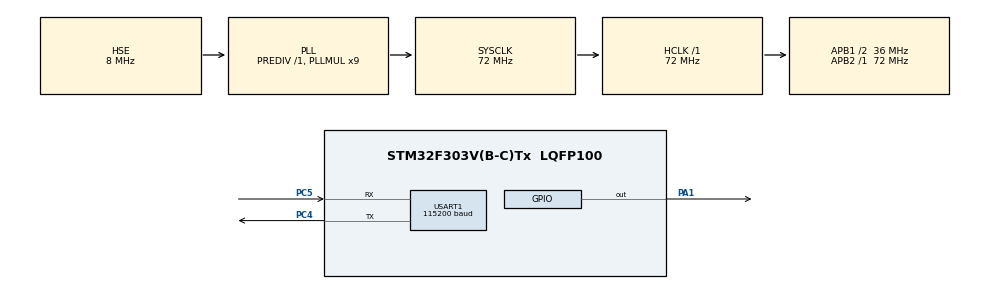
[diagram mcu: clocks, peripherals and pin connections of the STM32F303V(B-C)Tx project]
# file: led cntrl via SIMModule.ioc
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Mcu.Family=STM32F3
Mcu.Name=STM32F303V(B-C)Tx
Mcu.Package=LQFP100
NVIC.PriorityGroup=NVIC_PRIORITYGROUP_4
NVIC.USART1_IRQn=true\:0\:0\:false\:false\:true\:true\:true\:true
PA1.Signal=GPIO_Output
PA13.Mode=Serial_Wire
PA13.Signal=SYS_JTMS-SWDIO
PA14.Mode=Serial_Wire
PA14.Signal=SYS_JTCK-SWCLK
PC4.Mode=Asynchronous
PC4.Signal=USART1_TX
PC5.Mode=Asynchronous
PC5.Signal=USART1_RX
PF0-OSC_IN.Mode=HSE-External-Oscillator
PF0-OSC_IN.Signal=RCC_OSC_IN
PF1-OSC_OUT.Mode=HSE-External-Oscillator
PF1-OSC_OUT.Signal=RCC_OSC_OUT
ProjectManager.HeapSize=0x200
ProjectManager.StackSize=0x400
ProjectManager.TargetToolchain=STM32CubeIDE
RCC.AHBFreq_Value=72000000
RCC.APB1CLKDivider=RCC_HCLK_DIV2
RCC.APB1Freq_Value=36000000
RCC.APB1TimFreq_Value=72000000
RCC.APB2Freq_Value=72000000
RCC.APB2TimFreq_Value=72000000
RCC.CortexFreq_Value=72000000
RCC.HCLKFreq_Value=72000000
RCC.HSE_VALUE=8000000
RCC.HSI_VALUE=8000000
RCC.LSE_VALUE=32768
RCC.PLLMUL=RCC_PLL_MUL9
RCC.PLLSourceVirtual=RCC_PLLSOURCE_HSE
RCC.SYSCLKFreq_VALUE=72000000
RCC.SYSCLKSourceVirtual=RCC_SYSCLKSOURCE_PLLCLK
RCC.USBFreq_Value=72000000
USART1.BaudRate=115200
USART1.VirtualMode-Asynchronous=VM_ASYNC
board=custom

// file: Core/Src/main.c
/* USER CODE BEGIN Header */
/**
  ******************************************************************************
  * @file           : main.c
  * @brief          : Main program body
  ******************************************************************************
  * @attention
  *
  * Copyright (c) 2024 STMicroelectronics.
  * All rights reserved.
  *
  * This software is licensed under terms that can be found in the LICENSE file
  * in the root directory of this software component.
  * If no LICENSE file comes with this software, it is provided AS-IS.
  *
  ******************************************************************************
  */
/* USER CODE END Header */
#include "main.h"

/* USER CODE BEGIN Includes */
#include <string.h>
#include <stdio.h>

/* USER CODE END Includes */

UART_HandleTypeDef huart1;

/* USER CODE BEGIN PV */
#define PREF_SMS_STORAGE "\"SM\""
char ATcommand[80];
uint8_t ATisOK = 0;
uint8_t slot = 0;
uint8_t rx_buffer[100] = {0};
uint8_t rx_index = 0;
uint8_t rx_data;

/* USER CODE END PV */

void SystemClock_Config(void);
static void MX_GPIO_Init(void);
static void MX_USART1_UART_Init(void);

int main(void)
{

  /* MCU Configuration--------------------------------------------------------*/

  /* Reset of all peripherals, Initializes the Flash interface and the Systick. */
  HAL_Init();

  /* Configure the system clock */
  SystemClock_Config();

  /* Initialize all configured peripherals */
  MX_GPIO_Init();
  MX_USART1_UART_Init();
  /* USER CODE BEGIN 2 */

  // Wait until getting response OK to AT
  while(!ATisOK)
  {
    sprintf(ATcommand,"AT\r\n");
    HAL_UART_Transmit(&huart1,(uint8_t *)ATcommand,strlen(ATcommand),1000);
    HAL_UART_Receive (&huart1, rx_buffer, 100, 100);
    HAL_Delay(1000);
    if(strstr((char *)rx_buffer,"OK"))
    {
      ATisOK = 1;
    }
    HAL_Delay(1000);
    memset(rx_buffer,0,sizeof(rx_buffer));
  }
  // Send AT+CMGF=1
  sprintf(ATcommand,"AT+CMGF=1\r\n");
  HAL_UART_Transmit(&huart1,(uint8_t *)ATcommand,strlen(ATcommand),1000);
  HAL_UART_Receive (&huart1, rx_buffer, 100, 100);
  HAL_Delay(1000);
  memset(rx_buffer,0,sizeof(rx_buffer));
  // Send AT+CNMI=2,1 to enable notification when SMS arrives
  sprintf(ATcommand,"AT+CNMI=2,1\r\n");
  HAL_UART_Transmit(&huart1,(uint8_t *)ATcommand,strlen(ATcommand),1000);
  // Enabling interrupt receive
  HAL_UART_Receive_IT(&huart1,&rx_data,1);// receive data (one character only)
  /* USER CODE END 2 */

  /* Infinite loop */
  while (1)
  {

  }
}

void SystemClock_Config(void)
{
  RCC_OscInitTypeDef RCC_OscInitStruct = {0};
  RCC_ClkInitTypeDef RCC_ClkInitStruct = {0};
  RCC_PeriphCLKInitTypeDef PeriphClkInit = {0};

  /** Initializes the RCC Oscillators according to the specified parameters
  * in the RCC_OscInitTypeDef structure.
  */
  RCC_OscInitStruct.OscillatorType = RCC_OSCILLATORTYPE_HSE;
  RCC_OscInitStruct.HSEState = RCC_HSE_ON;
  RCC_OscInitStruct.HSEPredivValue = RCC_HSE_PREDIV_DIV1;
  RCC_OscInitStruct.HSIState = RCC_HSI_ON;
  RCC_OscInitStruct.PLL.PLLState = RCC_PLL_ON;
  RCC_OscInitStruct.PLL.PLLSource = RCC_PLLSOURCE_HSE;
  RCC_OscInitStruct.PLL.PLLMUL = RCC_PLL_MUL9;
  if (HAL_RCC_OscConfig(&RCC_OscInitStruct) != HAL_OK)
  {
    Error_Handler();
  }

  /** Initializes the CPU, AHB and APB buses clocks
  */
  RCC_ClkInitStruct.ClockType = RCC_CLOCKTYPE_HCLK|RCC_CLOCKTYPE_SYSCLK
                              |RCC_CLOCKTYPE_PCLK1|RCC_CLOCKTYPE_PCLK2;
  RCC_ClkInitStruct.SYSCLKSource = RCC_SYSCLKSOURCE_PLLCLK;
  RCC_ClkInitStruct.AHBCLKDivider = RCC_SYSCLK_DIV1;
  RCC_ClkInitStruct.APB1CLKDivider = RCC_HCLK_DIV2;
  RCC_ClkInitStruct.APB2CLKDivider = RCC_HCLK_DIV1;

  if (HAL_RCC_ClockConfig(&RCC_ClkInitStruct, FLASH_LATENCY_2) != HAL_OK)
  {
    Error_Handler();
  }
  PeriphClkInit.PeriphClockSelection = RCC_PERIPHCLK_USART1;
  PeriphClkInit.Usart1ClockSelection = RCC_USART1CLKSOURCE_PCLK2;
  if (HAL_RCCEx_PeriphCLKConfig(&PeriphClkInit) != HAL_OK)
  {
    Error_Handler();
  }
}

static void MX_USART1_UART_Init(void)
{

  huart1.Instance = USART1;
  huart1.Init.BaudRate = 115200;
  huart1.Init.WordLength = UART_WORDLENGTH_8B;
  huart1.Init.StopBits = UART_STOPBITS_1;
  huart1.Init.Parity = UART_PARITY_NONE;
  huart1.Init.Mode = UART_MODE_TX_RX;
  huart1.Init.HwFlowCtl = UART_HWCONTROL_NONE;
  huart1.Init.OverSampling = UART_OVERSAMPLING_16;
  huart1.Init.OneBitSampling = UART_ONE_BIT_SAMPLE_DISABLE;
  huart1.AdvancedInit.AdvFeatureInit = UART_ADVFEATURE_NO_INIT;
  if (HAL_UART_Init(&huart1) != HAL_OK)
  {
    Error_Handler();
  }

}

static void MX_GPIO_Init(void)
{
  GPIO_InitTypeDef GPIO_InitStruct = {0};

  /* GPIO Ports Clock Enable */
  __HAL_RCC_GPIOF_CLK_ENABLE();
  __HAL_RCC_GPIOA_CLK_ENABLE();
  __HAL_RCC_GPIOC_CLK_ENABLE();

  /*Configure GPIO pin Output Level */
  HAL_GPIO_WritePin(GPIOA, GPIO_PIN_1, GPIO_PIN_RESET);

  /*Configure GPIO pin : PA1 */
  GPIO_InitStruct.Pin = GPIO_PIN_1;
  GPIO_InitStruct.Mode = GPIO_MODE_OUTPUT_PP;
  GPIO_InitStruct.Pull = GPIO_NOPULL;
  GPIO_InitStruct.Speed = GPIO_SPEED_FREQ_LOW;
  HAL_GPIO_Init(GPIOA, &GPIO_InitStruct);

}

/* USER CODE BEGIN 4 */

void HAL_UART_RxCpltCallback(UART_HandleTypeDef *huart)
{
  if(huart->Instance==USART1)
  {
    // if the character received is other than 'enter' ascii13, save the data in buffer
    if(rx_data!=13)
    {
      rx_buffer[rx_index++]=rx_data;
    }
    else
    {
      // if new message arrived, read the message
      if( sscanf((char*)rx_buffer, "\n+CMTI: " PREF_SMS_STORAGE ",%hhd", &slot)==1)
      {
        sprintf(ATcommand,"AT+CMGR=%d\r\n",slot);
        HAL_UART_Transmit_IT(&huart1,(uint8_t *)ATcommand,strlen(ATcommand));
      }
      // if message read contains "ledon", switch the LED ON
      else if (strstr((char *)rx_buffer,"ledon"))
      {
        HAL_GPIO_WritePin(GPIOA, GPIO_PIN_1, 1);
      }
      // if message read contains "ledoff", switch the LED OFF
      else if (strstr((char *)rx_buffer,"ledoff"))
      {
        HAL_GPIO_WritePin(GPIOA, GPIO_PIN_1, 0);
      }
      // This will delete all messages in the SIM card. (Is it ok for you?)
      if (strstr((char *)rx_buffer,"READ"))
      {
          sprintf(ATcommand,"AT+CMGD=,4\r\n");
          HAL_UART_Transmit_IT(&huart1,(uint8_t *)ATcommand,strlen(ATcommand));
      }
      rx_index=0;
      memset(rx_buffer,0,sizeof(rx_buffer));
    }
    // Enabling interrupt receive again
    HAL_UART_Receive_IT(&huart1,&rx_data,1); // receive data (one character only)
  }
}
/* USER CODE END 4 */

void Error_Handler(void)
{
  __disable_irq();
  while (1)
  {
  }
}
